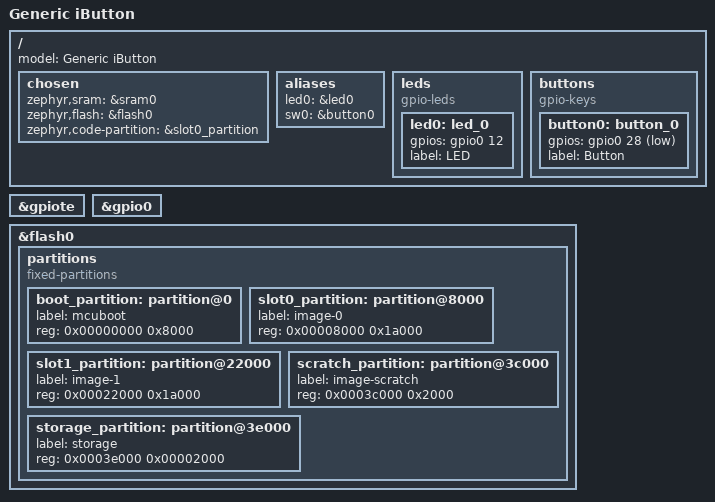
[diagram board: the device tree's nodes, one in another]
/dts-v1/;
#include <nordic/nrf51822_qfaa.dtsi>

/ {
	model = "Generic iButton";

	chosen {
	       /*
	        zephyr,console = &uart0;
		zephyr,shell-uart = &uart0;
		zephyr,uart-mcumgr = &uart0;
		zephyr,bt-mon-uart = &uart0;
		zephyr,bt-c2h-uart = &uart0;
		*/
		zephyr,sram = &sram0;
		zephyr,flash = &flash0;
		zephyr,code-partition = &slot0_partition;
	};

	aliases {
		led0 = &led0;
	};

	aliases {
		led0 = &led0;
		sw0 = &button0;
	};

	leds {
		compatible = "gpio-leds";
		led0: led_0 {
			gpios = <&gpio0 12 0>;
			label = "LED";
		};
	};

	buttons {
		compatible = "gpio-keys";
		button0: button_0 {
			/* gpio flags need validation */
			gpios = <&gpio0 28 (GPIO_PULL_UP | GPIO_ACTIVE_LOW)>;
			label = "Button";
		};
	};
};

&gpiote {
	status = "okay";
};

&gpio0 {
	status = "okay";
};

/*
&uart0 {
	current-speed = <115200>;
	status = "okay";
	tx-pin = <9>;
	rx-pin = <11>;
};

There is an i2c footprint for a kx11 IMS so TODO work out what pins it's on
&i2c0 {
	status = "okay";
	sda-pin = <20>;
	scl-pin = <21>;
};
*/

&flash0 {
	/*
	 * For more information, see:
	 * http://docs.zephyrproject.org/latest/guides/dts/index.html#flash-partitions
	 */
	partitions {
		compatible = "fixed-partitions";
		#address-cells = <1>;
		#size-cells = <1>;

		boot_partition: partition@0 {
			label = "mcuboot";
			reg = <0x00000000 0x8000>;
		};
		slot0_partition: partition@8000 {
			label = "image-0";
			reg = <0x00008000 0x1a000>;
		};
		slot1_partition: partition@22000 {
			label = "image-1";
			reg = <0x00022000 0x1a000>;
		};
		scratch_partition: partition@3c000 {
			label = "image-scratch";
			reg = <0x0003c000 0x2000>;
		};
		storage_partition: partition@3e000 {
			label = "storage";
			reg = <0x0003e000 0x00002000>;
		};
	};
};
